# STM8L151K3 register map
Vendor: STMicroelectronics; Series: STM8L/STM8AL, low density; File version: 1.0
CPU: other r1p0, big endian, no MPU, no FPU, 4 interrupt priority bits
Registers are 8-bit, read-write, reset 0x0 unless marked. A register's access mark holds for its fields unless they carry their own. Offsets are from the block's base; [hi:lo] are bit positions; {n}, {i} and the like mark numbered series.

## IRTIM
Base 0x000052FF
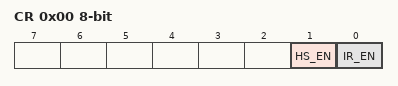
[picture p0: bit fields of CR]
0x00 CR — Infra-red control register
  [1] HS_EN, [0] IR_EN

## ITC_EXTI
Base 0x000050A0
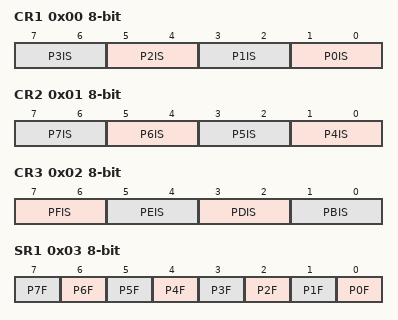
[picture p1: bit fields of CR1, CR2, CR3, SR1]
0x00 CR1 — External interrupt control register 1
  [2n+1:2n] P{n}IS (n=0..3)
0x01 CR2 — External interrupt control register 2
  [2n-7:2n-8] P{n}IS (n=4..7)
0x02 CR3 — External interrupt control register 3
  [7:6] PFIS, [5:4] PEIS, [3:2] PDIS, [1:0] PBIS
0x03 SR1 — External interrupt status register 1
  [n] P{n}F (n=0..7)
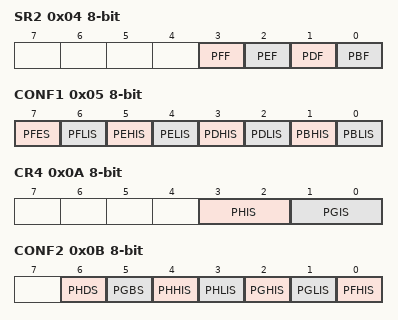
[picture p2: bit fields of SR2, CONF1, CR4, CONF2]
0x04 SR2 — External interrupt status register 2
  [3] PFF, [2] PEF, [1] PDF, [0] PBF
0x05 CONF1 — External interrupt port select register
  [7] PFES, [6] PFLIS, [5] PEHIS, [4] PELIS, [3] PDHIS, [2] PDLIS, [1] PBHIS, [0] PBLIS
0x0A CR4 — External interrupt control register 4
  [3:2] PHIS, [1:0] PGIS
0x0B CONF2 — External interrupt port select register 2
  [6] PHDS, [5] PGBS, [4] PHHIS, [3] PHLIS, [2] PGHIS, [1] PGLIS, [0] PFHIS

## ITC_SPR
Base 0x00007F70
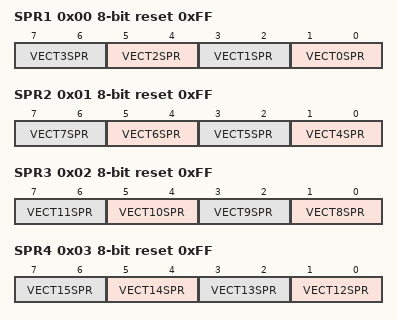
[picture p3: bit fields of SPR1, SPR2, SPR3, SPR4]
0x00 SPR1 reset 0xFF — Interrupt Software priority register 1
  [2n+1:2n] VECT{n}SPR (n=0..3)
0x01 SPR2 reset 0xFF — Interrupt Software priority register 2
  [2n-7:2n-8] VECT{n}SPR (n=4..7)
0x02 SPR3 reset 0xFF — Interrupt Software priority register 3
  [2n-15:2n-16] VECT{n}SPR (n=8..11)
0x03 SPR4 reset 0xFF — Interrupt Software priority register 4
  [2n-23:2n-24] VECT{n}SPR (n=12..15)
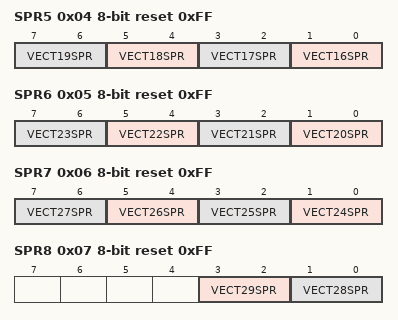
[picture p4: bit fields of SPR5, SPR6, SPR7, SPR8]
0x04 SPR5 reset 0xFF — Interrupt Software priority register 5
  [2n-31:2n-32] VECT{n}SPR (n=16..19)
0x05 SPR6 reset 0xFF — Interrupt Software priority register 6
  [2n-39:2n-40] VECT{n}SPR (n=20..23)
0x06 SPR7 reset 0xFF — Interrupt Software priority register 7
  [2n-47:2n-48] VECT{n}SPR (n=24..27)
0x07 SPR8 reset 0xFF — Interrupt Software priority register 8
  [3:2] VECT29SPR, [1:0] VECT28SPR

## IWDG
Base 0x000050E0
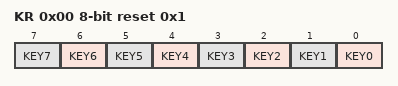
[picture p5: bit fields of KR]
0x00 KR reset 0x1 — IWDG key register
  [n] KEY{n} (n=0..7)
0x01 PR — IWDG prescaler register
  [2:0] PR
0x02 RLR reset 0xFF — IWDG reload register
  [7:0] RL

## OPT
Base 0x00004800
0x00 OPT0 reset 0xAA — Read-out protection (ROP)
0x02 OPT1 — User boot code (UBC)
0x08 OPT3 — Watchdog option
0x09 OPT4 — Clock option
0x0A OPT5 reset 0x1 — Brownout reset (BOR)
0x0B OPTBL_H — Bootloader (high byte)
0x0C OPTBL_L — Bootloader (low byte)

## PWR
Base 0x000050B2
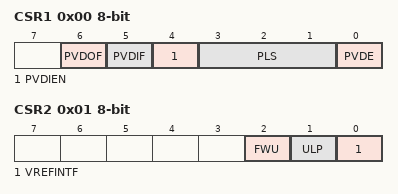
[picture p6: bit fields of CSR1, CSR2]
0x00 CSR1 — Power control and status register 1
  [6] PVDOF, [5] PVDIF, [4] PVDIEN, [3:1] PLS, [0] PVDE
0x01 CSR2 — Power control and status register 2
  [2] FWU, [1] ULP, [0] VREFINTF

## PORTA
Base 0x00005000
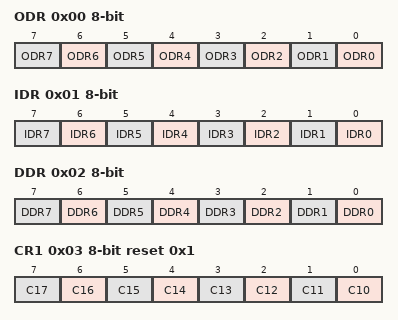
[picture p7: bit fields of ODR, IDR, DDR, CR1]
0x00 ODR — Port A data output latch register
  [n] ODR{n} (n=0..7)
0x01 IDR — Port A input pin value register
  [n] IDR{n} (n=0..7)
0x02 DDR — Port A data direction register
  [n] DDR{n} (n=0..7)
0x03 CR1 reset 0x1 — Port A control register 1
  [n-10] C{n} (n=10..17)
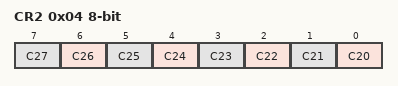
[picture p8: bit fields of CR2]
0x04 CR2 — Port A control register 2
  [n-20] C{n} (n=20..27)

## PORTB
Base 0x00005005
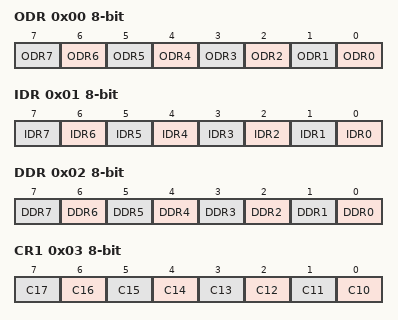
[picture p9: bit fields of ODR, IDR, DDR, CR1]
0x00 ODR — Port B data output latch register
  [n] ODR{n} (n=0..7)
0x01 IDR — Port B input pin value register
  [n] IDR{n} (n=0..7)
0x02 DDR — Port B data direction register
  [n] DDR{n} (n=0..7)
0x03 CR1 — Port B control register 1
  [n-10] C{n} (n=10..17)
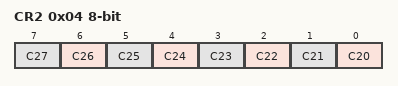
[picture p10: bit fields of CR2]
0x04 CR2 — Port B control register 2
  [n-20] C{n} (n=20..27)

## PORTC
Base 0x0000500A
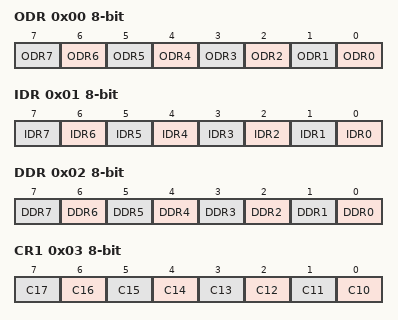
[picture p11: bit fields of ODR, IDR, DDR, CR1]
0x00 ODR — Port C data output latch register
  [n] ODR{n} (n=0..7)
0x01 IDR — Port C input pin value register
  [n] IDR{n} (n=0..7)
0x02 DDR — Port C data direction register
  [n] DDR{n} (n=0..7)
0x03 CR1 — Port C control register 1
  [n-10] C{n} (n=10..17)
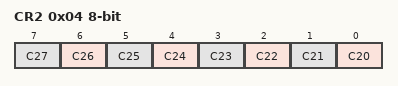
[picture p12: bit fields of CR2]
0x04 CR2 — Port C control register 2
  [n-20] C{n} (n=20..27)

## PORTD
Base 0x0000500F
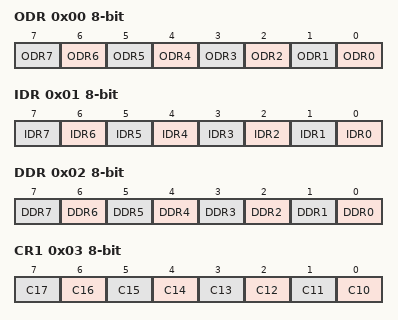
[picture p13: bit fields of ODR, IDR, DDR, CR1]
0x00 ODR — Port D data output latch register
  [n] ODR{n} (n=0..7)
0x01 IDR — Port D input pin value register
  [n] IDR{n} (n=0..7)
0x02 DDR — Port D data direction register
  [n] DDR{n} (n=0..7)
0x03 CR1 — Port D control register 1
  [n-10] C{n} (n=10..17)
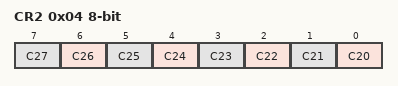
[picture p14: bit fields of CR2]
0x04 CR2 — Port D control register 2
  [n-20] C{n} (n=20..27)
